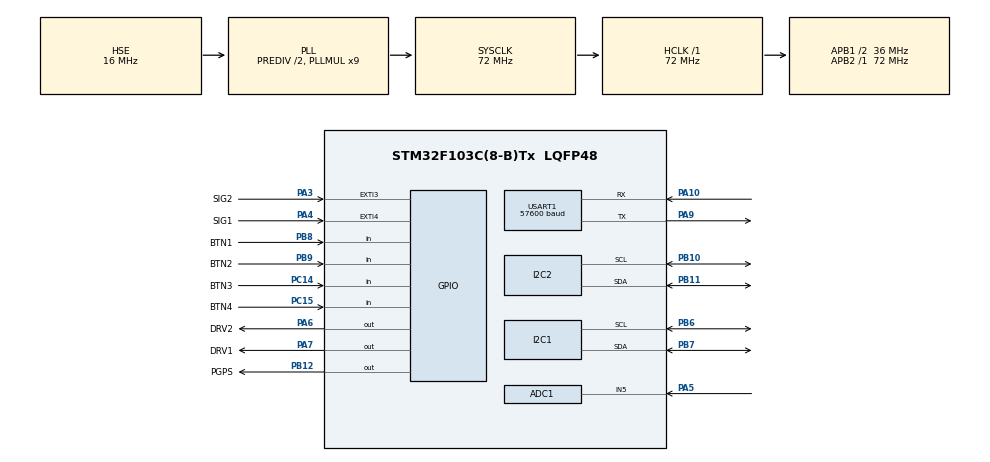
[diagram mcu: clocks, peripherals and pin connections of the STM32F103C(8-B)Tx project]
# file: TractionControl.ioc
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ADC1.Channel-0\#ChannelRegularConversion=ADC_CHANNEL_5
ADC1.NbrOfConversion=1
ADC1.NbrOfConversionFlag=1
ADC1.Rank-0\#ChannelRegularConversion=1
ADC1.SamplingTime-0\#ChannelRegularConversion=ADC_SAMPLETIME_55CYCLES_5
ADC1.master=1
Dma.ADC1.0.Direction=DMA_PERIPH_TO_MEMORY
Dma.ADC1.0.Instance=DMA1_Channel1
Dma.ADC1.0.MemDataAlignment=DMA_MDATAALIGN_HALFWORD
Dma.ADC1.0.MemInc=DMA_MINC_ENABLE
Dma.ADC1.0.Mode=DMA_NORMAL
Dma.ADC1.0.PeriphDataAlignment=DMA_PDATAALIGN_HALFWORD
Dma.ADC1.0.PeriphInc=DMA_PINC_DISABLE
Dma.ADC1.0.Priority=DMA_PRIORITY_LOW
Dma.Request0=ADC1
Dma.Request1=USART1_RX
Dma.USART1_RX.1.Direction=DMA_PERIPH_TO_MEMORY
Dma.USART1_RX.1.Instance=DMA1_Channel5
Dma.USART1_RX.1.MemDataAlignment=DMA_MDATAALIGN_BYTE
Dma.USART1_RX.1.MemInc=DMA_MINC_ENABLE
Dma.USART1_RX.1.Mode=DMA_NORMAL
Dma.USART1_RX.1.PeriphDataAlignment=DMA_PDATAALIGN_BYTE
Dma.USART1_RX.1.PeriphInc=DMA_PINC_DISABLE
Dma.USART1_RX.1.Priority=DMA_PRIORITY_LOW
Mcu.Family=STM32F1
Mcu.Name=STM32F103C(8-B)Tx
Mcu.Package=LQFP48
NVIC.DMA1_Channel1_IRQn=true\:0\:0\:false\:false\:true\:false\:true\:true
NVIC.DMA1_Channel5_IRQn=true\:0\:0\:false\:false\:true\:false\:true\:true
NVIC.EXTI3_IRQn=true\:0\:0\:false\:false\:true\:true\:true\:true
NVIC.EXTI4_IRQn=true\:0\:0\:false\:false\:true\:true\:true\:true
NVIC.PriorityGroup=NVIC_PRIORITYGROUP_4
NVIC.TIM1_UP_IRQn=true\:0\:0\:false\:false\:true\:true\:true\:true
NVIC.TIM2_IRQn=true\:0\:0\:false\:false\:true\:true\:true\:true
NVIC.TIM3_IRQn=true\:0\:0\:false\:false\:true\:true\:true\:true
PA10.Mode=Asynchronous
PA10.Signal=USART1_RX
PA13.Mode=Trace_Asynchronous_SW
PA13.Signal=SYS_JTMS-SWDIO
PA14.Mode=Trace_Asynchronous_SW
PA14.Signal=SYS_JTCK-SWCLK
PA3.GPIO_Label=SIG2
PA3.Signal=GPXTI3
PA4.GPIO_Label=SIG1
PA4.Signal=GPXTI4
PA5.Signal=ADCx_IN5
PA6.GPIO_Label=DRV2
PA6.Signal=GPIO_Output
PA7.GPIO_Label=DRV1
PA7.Signal=GPIO_Output
PA9.Mode=Asynchronous
PA9.Signal=USART1_TX
PB10.Mode=I2C
PB10.Signal=I2C2_SCL
PB11.Mode=I2C
PB11.Signal=I2C2_SDA
PB12.GPIO_Label=PGPS
PB12.Signal=GPIO_Output
PB3.Mode=Trace_Asynchronous_SW
PB3.Signal=SYS_JTDO-TRACESWO
PB6.Mode=I2C
PB6.Signal=I2C1_SCL
PB7.Mode=I2C
PB7.Signal=I2C1_SDA
PB8.GPIO_Label=BTN1
PB8.GPIO_PuPd=GPIO_PULLUP
PB8.Signal=GPIO_Input
PB9.GPIO_Label=BTN2
PB9.GPIO_PuPd=GPIO_PULLUP
PB9.Signal=GPIO_Input
PC14-OSC32_IN.GPIO_Label=BTN3
PC14-OSC32_IN.GPIO_PuPd=GPIO_PULLUP
PC14-OSC32_IN.Signal=GPIO_Input
PC15-OSC32_OUT.GPIO_Label=BTN4
PC15-OSC32_OUT.GPIO_PuPd=GPIO_PULLUP
PC15-OSC32_OUT.Signal=GPIO_Input
PD0-OSC_IN.Mode=HSE-External-Oscillator
PD0-OSC_IN.Signal=RCC_OSC_IN
PD1-OSC_OUT.Mode=HSE-External-Oscillator
PD1-OSC_OUT.Signal=RCC_OSC_OUT
ProjectManager.HeapSize=0x200
ProjectManager.StackSize=0x400
ProjectManager.TargetToolchain=STM32CubeIDE
RCC.ADCPresc=RCC_ADCPCLK2_DIV6
RCC.AHBFreq_Value=72000000
RCC.APB1CLKDivider=RCC_HCLK_DIV2
RCC.APB1Freq_Value=36000000
RCC.APB1TimFreq_Value=72000000
RCC.APB2Freq_Value=72000000
RCC.APB2TimFreq_Value=72000000
RCC.HCLKFreq_Value=72000000
RCC.HSEDivPLL=RCC_HSE_PREDIV_DIV2
RCC.HSE_VALUE=16000000
RCC.PLLMUL=RCC_PLL_MUL9
RCC.PLLSourceVirtual=RCC_PLLSOURCE_HSE
RCC.SYSCLKFreq_VALUE=72000000
RCC.SYSCLKSource=RCC_SYSCLKSOURCE_PLLCLK
RCC.USBFreq_Value=72000000
SH.ADCx_IN5.0=ADC1_IN5,IN5
TIM1.Period=200-1
TIM1.Prescaler=7200-1
TIM2.Period=20-1
TIM2.Prescaler=72-1
TIM3.Period=200-1
TIM3.Prescaler=7200-1
USART1.BaudRate=57600
USART1.Mode=MODE_RX
USART1.VirtualMode=VM_ASYNC
VP_TIM1_VS_ClockSourceINT.Mode=Internal
VP_TIM2_VS_ClockSourceINT.Mode=Internal
VP_TIM3_VS_ClockSourceINT.Mode=Internal
board=custom

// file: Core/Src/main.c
/* USER CODE BEGIN Header */
/**
  ******************************************************************************
  * @file           : main.c
  * @brief          : Main program body
  ******************************************************************************
  * @attention
  *
  * Copyright (c) 2024 STMicroelectronics.
  * All rights reserved.
  *
  * This software is licensed under terms that can be found in the LICENSE file
  * in the root directory of this software component.
  * If no LICENSE file comes with this software, it is provided AS-IS.
  *
  ******************************************************************************
  */
/* USER CODE END Header */
#include "main.h"

/* USER CODE BEGIN Includes */
#include "control.h"
/* USER CODE END Includes */

ADC_HandleTypeDef hadc1;
DMA_HandleTypeDef hdma_adc1;

I2C_HandleTypeDef hi2c1;
I2C_HandleTypeDef hi2c2;

TIM_HandleTypeDef htim1;
TIM_HandleTypeDef htim2;
TIM_HandleTypeDef htim3;

UART_HandleTypeDef huart1;
DMA_HandleTypeDef hdma_usart1_rx;

void SystemClock_Config(void);
static void MX_GPIO_Init(void);
static void MX_DMA_Init(void);
static void MX_ADC1_Init(void);
static void MX_I2C1_Init(void);
static void MX_I2C2_Init(void);
static void MX_USART1_UART_Init(void);
static void MX_TIM1_Init(void);
static void MX_TIM2_Init(void);
static void MX_TIM3_Init(void);

int main(void)
{

  /* MCU Configuration--------------------------------------------------------*/

  /* Reset of all peripherals, Initializes the Flash interface and the Systick. */
  HAL_Init();

  /* Configure the system clock */
  SystemClock_Config();

  /* Initialize all configured peripherals */
  MX_GPIO_Init();
  MX_DMA_Init();
  MX_ADC1_Init();
  MX_I2C1_Init();
  MX_I2C2_Init();
  MX_USART1_UART_Init();
  MX_TIM1_Init();
  MX_TIM2_Init();
  MX_TIM3_Init();

  /* Infinite loop */
  /* USER CODE BEGIN WHILE */
  HAL_Delay(10);
  Control_Init();
  HAL_Delay(10);
  while (1)
  {
	  Control_Loop();
    /* USER CODE END WHILE */

  }
}

void SystemClock_Config(void)
{
  RCC_OscInitTypeDef RCC_OscInitStruct = {0};
  RCC_ClkInitTypeDef RCC_ClkInitStruct = {0};
  RCC_PeriphCLKInitTypeDef PeriphClkInit = {0};

  /** Initializes the RCC Oscillators according to the specified parameters
  * in the RCC_OscInitTypeDef structure.
  */
  RCC_OscInitStruct.OscillatorType = RCC_OSCILLATORTYPE_HSE;
  RCC_OscInitStruct.HSEState = RCC_HSE_ON;
  RCC_OscInitStruct.HSEPredivValue = RCC_HSE_PREDIV_DIV2;
  RCC_OscInitStruct.HSIState = RCC_HSI_ON;
  RCC_OscInitStruct.PLL.PLLState = RCC_PLL_ON;
  RCC_OscInitStruct.PLL.PLLSource = RCC_PLLSOURCE_HSE;
  RCC_OscInitStruct.PLL.PLLMUL = RCC_PLL_MUL9;
  if (HAL_RCC_OscConfig(&RCC_OscInitStruct) != HAL_OK)
  {
    Error_Handler();
  }

  /** Initializes the CPU, AHB and APB buses clocks
  */
  RCC_ClkInitStruct.ClockType = RCC_CLOCKTYPE_HCLK|RCC_CLOCKTYPE_SYSCLK
                              |RCC_CLOCKTYPE_PCLK1|RCC_CLOCKTYPE_PCLK2;
  RCC_ClkInitStruct.SYSCLKSource = RCC_SYSCLKSOURCE_PLLCLK;
  RCC_ClkInitStruct.AHBCLKDivider = RCC_SYSCLK_DIV1;
  RCC_ClkInitStruct.APB1CLKDivider = RCC_HCLK_DIV2;
  RCC_ClkInitStruct.APB2CLKDivider = RCC_HCLK_DIV1;

  if (HAL_RCC_ClockConfig(&RCC_ClkInitStruct, FLASH_LATENCY_2) != HAL_OK)
  {
    Error_Handler();
  }
  PeriphClkInit.PeriphClockSelection = RCC_PERIPHCLK_ADC;
  PeriphClkInit.AdcClockSelection = RCC_ADCPCLK2_DIV6;
  if (HAL_RCCEx_PeriphCLKConfig(&PeriphClkInit) != HAL_OK)
  {
    Error_Handler();
  }
}

static void MX_ADC1_Init(void)
{

  ADC_ChannelConfTypeDef sConfig = {0};

  /** Common config
  */
  hadc1.Instance = ADC1;
  hadc1.Init.ScanConvMode = ADC_SCAN_DISABLE;
  hadc1.Init.ContinuousConvMode = DISABLE;
  hadc1.Init.DiscontinuousConvMode = DISABLE;
  hadc1.Init.ExternalTrigConv = ADC_SOFTWARE_START;
  hadc1.Init.DataAlign = ADC_DATAALIGN_RIGHT;
  hadc1.Init.NbrOfConversion = 1;
  if (HAL_ADC_Init(&hadc1) != HAL_OK)
  {
    Error_Handler();
  }

  /** Configure Regular Channel
  */
  sConfig.Channel = ADC_CHANNEL_5;
  sConfig.Rank = ADC_REGULAR_RANK_1;
  sConfig.SamplingTime = ADC_SAMPLETIME_55CYCLES_5;
  if (HAL_ADC_ConfigChannel(&hadc1, &sConfig) != HAL_OK)
  {
    Error_Handler();
  }

}

static void MX_I2C1_Init(void)
{

  hi2c1.Instance = I2C1;
  hi2c1.Init.ClockSpeed = 100000;
  hi2c1.Init.DutyCycle = I2C_DUTYCYCLE_2;
  hi2c1.Init.OwnAddress1 = 0;
  hi2c1.Init.AddressingMode = I2C_ADDRESSINGMODE_7BIT;
  hi2c1.Init.DualAddressMode = I2C_DUALADDRESS_DISABLE;
  hi2c1.Init.OwnAddress2 = 0;
  hi2c1.Init.GeneralCallMode = I2C_GENERALCALL_DISABLE;
  hi2c1.Init.NoStretchMode = I2C_NOSTRETCH_DISABLE;
  if (HAL_I2C_Init(&hi2c1) != HAL_OK)
  {
    Error_Handler();
  }

}

static void MX_I2C2_Init(void)
{

  hi2c2.Instance = I2C2;
  hi2c2.Init.ClockSpeed = 100000;
  hi2c2.Init.DutyCycle = I2C_DUTYCYCLE_2;
  hi2c2.Init.OwnAddress1 = 0;
  hi2c2.Init.AddressingMode = I2C_ADDRESSINGMODE_7BIT;
  hi2c2.Init.DualAddressMode = I2C_DUALADDRESS_DISABLE;
  hi2c2.Init.OwnAddress2 = 0;
  hi2c2.Init.GeneralCallMode = I2C_GENERALCALL_DISABLE;
  hi2c2.Init.NoStretchMode = I2C_NOSTRETCH_DISABLE;
  if (HAL_I2C_Init(&hi2c2) != HAL_OK)
  {
    Error_Handler();
  }

}

static void MX_TIM1_Init(void)
{

  TIM_ClockConfigTypeDef sClockSourceConfig = {0};
  TIM_MasterConfigTypeDef sMasterConfig = {0};

  htim1.Instance = TIM1;
  htim1.Init.Prescaler = 7200-1;
  htim1.Init.CounterMode = TIM_COUNTERMODE_UP;
  htim1.Init.Period = 200-1;
  htim1.Init.ClockDivision = TIM_CLOCKDIVISION_DIV1;
  htim1.Init.RepetitionCounter = 0;
  htim1.Init.AutoReloadPreload = TIM_AUTORELOAD_PRELOAD_DISABLE;
  if (HAL_TIM_Base_Init(&htim1) != HAL_OK)
  {
    Error_Handler();
  }
  sClockSourceConfig.ClockSource = TIM_CLOCKSOURCE_INTERNAL;
  if (HAL_TIM_ConfigClockSource(&htim1, &sClockSourceConfig) != HAL_OK)
  {
    Error_Handler();
  }
  sMasterConfig.MasterOutputTrigger = TIM_TRGO_RESET;
  sMasterConfig.MasterSlaveMode = TIM_MASTERSLAVEMODE_DISABLE;
  if (HAL_TIMEx_MasterConfigSynchronization(&htim1, &sMasterConfig) != HAL_OK)
  {
    Error_Handler();
  }

}

static void MX_TIM2_Init(void)
{

  TIM_ClockConfigTypeDef sClockSourceConfig = {0};
  TIM_MasterConfigTypeDef sMasterConfig = {0};

  htim2.Instance = TIM2;
  htim2.Init.Prescaler = 72-1;
  htim2.Init.CounterMode = TIM_COUNTERMODE_UP;
  htim2.Init.Period = 20-1;
  htim2.Init.ClockDivision = TIM_CLOCKDIVISION_DIV1;
  htim2.Init.AutoReloadPreload = TIM_AUTORELOAD_PRELOAD_DISABLE;
  if (HAL_TIM_Base_Init(&htim2) != HAL_OK)
  {
    Error_Handler();
  }
  sClockSourceConfig.ClockSource = TIM_CLOCKSOURCE_INTERNAL;
  if (HAL_TIM_ConfigClockSource(&htim2, &sClockSourceConfig) != HAL_OK)
  {
    Error_Handler();
  }
  sMasterConfig.MasterOutputTrigger = TIM_TRGO_RESET;
  sMasterConfig.MasterSlaveMode = TIM_MASTERSLAVEMODE_DISABLE;
  if (HAL_TIMEx_MasterConfigSynchronization(&htim2, &sMasterConfig) != HAL_OK)
  {
    Error_Handler();
  }

}

static void MX_TIM3_Init(void)
{

  TIM_ClockConfigTypeDef sClockSourceConfig = {0};
  TIM_MasterConfigTypeDef sMasterConfig = {0};

  htim3.Instance = TIM3;
  htim3.Init.Prescaler = 7200-1;
  htim3.Init.CounterMode = TIM_COUNTERMODE_UP;
  htim3.Init.Period = 200-1;
  htim3.Init.ClockDivision = TIM_CLOCKDIVISION_DIV1;
  htim3.Init.AutoReloadPreload = TIM_AUTORELOAD_PRELOAD_DISABLE;
  if (HAL_TIM_Base_Init(&htim3) != HAL_OK)
  {
    Error_Handler();
  }
  sClockSourceConfig.ClockSource = TIM_CLOCKSOURCE_INTERNAL;
  if (HAL_TIM_ConfigClockSource(&htim3, &sClockSourceConfig) != HAL_OK)
  {
    Error_Handler();
  }
  sMasterConfig.MasterOutputTrigger = TIM_TRGO_RESET;
  sMasterConfig.MasterSlaveMode = TIM_MASTERSLAVEMODE_DISABLE;
  if (HAL_TIMEx_MasterConfigSynchronization(&htim3, &sMasterConfig) != HAL_OK)
  {
    Error_Handler();
  }

}

static void MX_USART1_UART_Init(void)
{

  huart1.Instance = USART1;
  huart1.Init.BaudRate = 57600;
  huart1.Init.WordLength = UART_WORDLENGTH_8B;
  huart1.Init.StopBits = UART_STOPBITS_1;
  huart1.Init.Parity = UART_PARITY_NONE;
  huart1.Init.Mode = UART_MODE_RX;
  huart1.Init.HwFlowCtl = UART_HWCONTROL_NONE;
  huart1.Init.OverSampling = UART_OVERSAMPLING_16;
  if (HAL_UART_Init(&huart1) != HAL_OK)
  {
    Error_Handler();
  }

}

static void MX_DMA_Init(void)
{

  /* DMA controller clock enable */
  __HAL_RCC_DMA1_CLK_ENABLE();

  /* DMA interrupt init */
  /* DMA1_Channel1_IRQn interrupt configuration */
  HAL_NVIC_SetPriority(DMA1_Channel1_IRQn, 0, 0);
  HAL_NVIC_EnableIRQ(DMA1_Channel1_IRQn);
  /* DMA1_Channel5_IRQn interrupt configuration */
  HAL_NVIC_SetPriority(DMA1_Channel5_IRQn, 0, 0);
  HAL_NVIC_EnableIRQ(DMA1_Channel5_IRQn);

}

static void MX_GPIO_Init(void)
{
  GPIO_InitTypeDef GPIO_InitStruct = {0};

  /* GPIO Ports Clock Enable */
  __HAL_RCC_GPIOC_CLK_ENABLE();
  __HAL_RCC_GPIOD_CLK_ENABLE();
  __HAL_RCC_GPIOA_CLK_ENABLE();
  __HAL_RCC_GPIOB_CLK_ENABLE();

  /*Configure GPIO pin Output Level */
  HAL_GPIO_WritePin(GPIOA, DRV2_Pin|DRV1_Pin, GPIO_PIN_RESET);

  /*Configure GPIO pin Output Level */
  HAL_GPIO_WritePin(PGPS_GPIO_Port, PGPS_Pin, GPIO_PIN_RESET);

  /*Configure GPIO pins : BTN3_Pin BTN4_Pin */
  GPIO_InitStruct.Pin = BTN3_Pin|BTN4_Pin;
  GPIO_InitStruct.Mode = GPIO_MODE_INPUT;
  GPIO_InitStruct.Pull = GPIO_PULLUP;
  HAL_GPIO_Init(GPIOC, &GPIO_InitStruct);

  /*Configure GPIO pins : SIG2_Pin SIG1_Pin */
  GPIO_InitStruct.Pin = SIG2_Pin|SIG1_Pin;
  GPIO_InitStruct.Mode = GPIO_MODE_IT_RISING;
  GPIO_InitStruct.Pull = GPIO_NOPULL;
  HAL_GPIO_Init(GPIOA, &GPIO_InitStruct);

  /*Configure GPIO pins : DRV2_Pin DRV1_Pin */
  GPIO_InitStruct.Pin = DRV2_Pin|DRV1_Pin;
  GPIO_InitStruct.Mode = GPIO_MODE_OUTPUT_PP;
  GPIO_InitStruct.Pull = GPIO_NOPULL;
  GPIO_InitStruct.Speed = GPIO_SPEED_FREQ_LOW;
  HAL_GPIO_Init(GPIOA, &GPIO_InitStruct);

  /*Configure GPIO pin : PGPS_Pin */
  GPIO_InitStruct.Pin = PGPS_Pin;
  GPIO_InitStruct.Mode = GPIO_MODE_OUTPUT_PP;
  GPIO_InitStruct.Pull = GPIO_NOPULL;
  GPIO_InitStruct.Speed = GPIO_SPEED_FREQ_LOW;
  HAL_GPIO_Init(PGPS_GPIO_Port, &GPIO_InitStruct);

  /*Configure GPIO pins : BTN1_Pin BTN2_Pin */
  GPIO_InitStruct.Pin = BTN1_Pin|BTN2_Pin;
  GPIO_InitStruct.Mode = GPIO_MODE_INPUT;
  GPIO_InitStruct.Pull = GPIO_PULLUP;
  HAL_GPIO_Init(GPIOB, &GPIO_InitStruct);

  /* EXTI interrupt init*/
  HAL_NVIC_SetPriority(EXTI3_IRQn, 0, 0);
  HAL_NVIC_EnableIRQ(EXTI3_IRQn);

  HAL_NVIC_SetPriority(EXTI4_IRQn, 0, 0);
  HAL_NVIC_EnableIRQ(EXTI4_IRQn);

}

void Error_Handler(void)
{
  __disable_irq();
  while (1)
  {
  }
}
